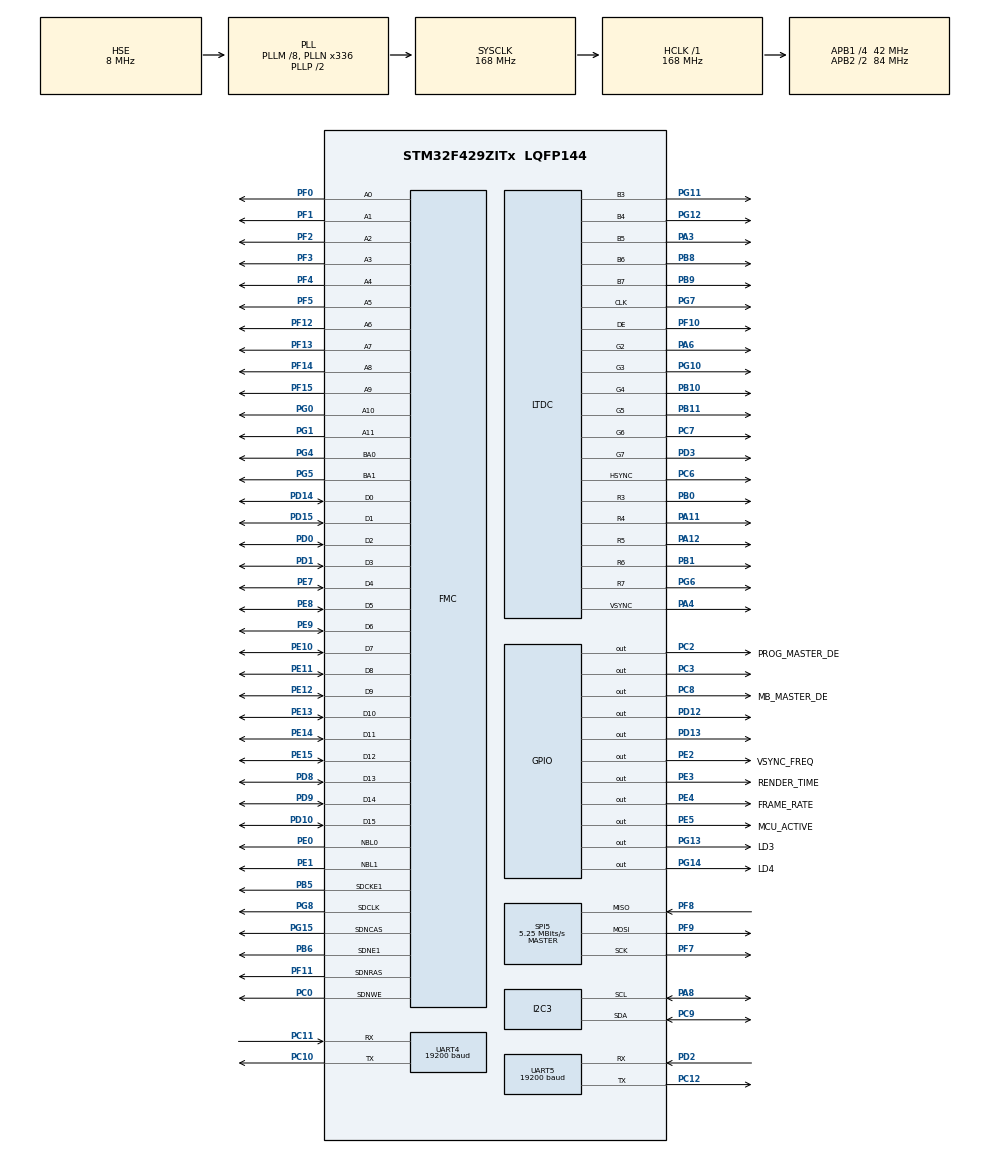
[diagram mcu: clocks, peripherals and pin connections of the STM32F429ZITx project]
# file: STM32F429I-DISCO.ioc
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DMA2D.ColorMode=DMA2D_OUTPUT_RGB565
Dma.Request0=UART5_RX
Dma.Request1=UART5_TX
Dma.Request2=UART4_RX
Dma.Request3=UART4_TX
Dma.UART4_RX.2.Direction=DMA_PERIPH_TO_MEMORY
Dma.UART4_RX.2.FIFOMode=DMA_FIFOMODE_DISABLE
Dma.UART4_RX.2.Instance=DMA1_Stream2
Dma.UART4_RX.2.MemDataAlignment=DMA_MDATAALIGN_BYTE
Dma.UART4_RX.2.MemInc=DMA_MINC_ENABLE
Dma.UART4_RX.2.Mode=DMA_NORMAL
Dma.UART4_RX.2.PeriphDataAlignment=DMA_PDATAALIGN_BYTE
Dma.UART4_RX.2.PeriphInc=DMA_PINC_DISABLE
Dma.UART4_RX.2.Priority=DMA_PRIORITY_LOW
Dma.UART4_TX.3.Direction=DMA_MEMORY_TO_PERIPH
Dma.UART4_TX.3.FIFOMode=DMA_FIFOMODE_DISABLE
Dma.UART4_TX.3.Instance=DMA1_Stream4
Dma.UART4_TX.3.MemDataAlignment=DMA_MDATAALIGN_BYTE
Dma.UART4_TX.3.MemInc=DMA_MINC_ENABLE
Dma.UART4_TX.3.Mode=DMA_NORMAL
Dma.UART4_TX.3.PeriphDataAlignment=DMA_PDATAALIGN_BYTE
Dma.UART4_TX.3.PeriphInc=DMA_PINC_DISABLE
Dma.UART4_TX.3.Priority=DMA_PRIORITY_LOW
Dma.UART5_RX.0.Direction=DMA_PERIPH_TO_MEMORY
Dma.UART5_RX.0.FIFOMode=DMA_FIFOMODE_DISABLE
Dma.UART5_RX.0.Instance=DMA1_Stream0
Dma.UART5_RX.0.MemDataAlignment=DMA_MDATAALIGN_BYTE
Dma.UART5_RX.0.MemInc=DMA_MINC_ENABLE
Dma.UART5_RX.0.Mode=DMA_NORMAL
Dma.UART5_RX.0.PeriphDataAlignment=DMA_PDATAALIGN_BYTE
Dma.UART5_RX.0.PeriphInc=DMA_PINC_DISABLE
Dma.UART5_RX.0.Priority=DMA_PRIORITY_LOW
Dma.UART5_TX.1.Direction=DMA_MEMORY_TO_PERIPH
Dma.UART5_TX.1.FIFOMode=DMA_FIFOMODE_DISABLE
Dma.UART5_TX.1.Instance=DMA1_Stream7
Dma.UART5_TX.1.MemDataAlignment=DMA_MDATAALIGN_BYTE
Dma.UART5_TX.1.MemInc=DMA_MINC_ENABLE
Dma.UART5_TX.1.Mode=DMA_NORMAL
Dma.UART5_TX.1.PeriphDataAlignment=DMA_PDATAALIGN_BYTE
Dma.UART5_TX.1.PeriphInc=DMA_PINC_DISABLE
Dma.UART5_TX.1.Priority=DMA_PRIORITY_LOW
FMC.CASLatency1=FMC_SDRAM_CAS_LATENCY_3
FMC.ExitSelfRefreshDelay1=7
FMC.LoadToActiveDelay1=2
FMC.RCDDelay1=2
FMC.RPDelay1=2
FMC.ReadPipeDelay1=FMC_SDRAM_RPIPE_DELAY_1
FMC.RowCycleDelay1=7
FMC.SDClockPeriod1=FMC_SDRAM_CLOCK_PERIOD_2
FMC.SelfRefreshTime1=4
FMC.WriteRecoveryTime1=3
FREERTOS.BinarySemaphores01=TX_Compl_Sem,Dynamic,NULL,;RX_Compl_Sem,Dynamic,NULL,;PR_TX_Compl_Sem,Dynamic,NULL,;PR_RX_Compl_Sem,Dynamic,NULL,;DataAnalysisStart,Dynamic,NULL,Depleted
FREERTOS.Events01=ReadDataEvent,Dynamic,NULL
FREERTOS.Tasks01=defaultTask,24,128,StartDefaultTask,Default,NULL,Dynamic,NULL,NULL;GUI_Task,24,8192,TouchGFX_Task,As external,NULL,Dynamic,NULL,NULL;DataProcessing,8,128,HandleDataProcessing,Default,NULL,Dynamic,NULL,NULL;ReadData,8,512,ReadDataFunction,Default,NULL,Dynamic,NULL,NULL
FREERTOS.Timers01=DataTimer,Callback01,osTimerPeriodic,Default,NULL,Dynamic,NULL
FREERTOS.configGENERATE_RUN_TIME_STATS=1
FREERTOS.configMAX_PRIORITIES=56
FREERTOS.configRECORD_STACK_HIGH_ADDRESS=1
FREERTOS.configTOTAL_HEAP_SIZE=65536
FREERTOS.configUSE_APPLICATION_TASK_TAG=1
FREERTOS.configUSE_NEWLIB_REENTRANT=1
FREERTOS.configUSE_STATS_FORMATTING_FUNCTIONS=1
I2C3.Analog_Filter=I2C_ANALOGFILTER_DISABLE
LTDC.ActiveH=320
LTDC.ActiveW=240
LTDC.Alpha_L0=255
LTDC.BlendingFactor1_L0=LTDC_BLENDING_FACTOR1_CA
LTDC.BlendingFactor2_L0=LTDC_BLENDING_FACTOR2_CA
LTDC.Blue_L0=0
LTDC.HBP=20
LTDC.HFP=10
LTDC.HSync=10
LTDC.ImageHeight_L0=320
LTDC.ImageWidth_L0=240
LTDC.Layers=0
LTDC.PixelFormat_L0=LTDC_PIXEL_FORMAT_RGB565
LTDC.VFP=4
LTDC.VSync=2
LTDC.WindowX1_L0=240
LTDC.WindowY1_L0=320
Mcu.Family=STM32F4
Mcu.Name=STM32F429ZITx
Mcu.Package=LQFP144
NVIC.DMA1_Stream0_IRQn=true\:5\:0\:false\:false\:true\:true\:false\:true\:true
NVIC.DMA1_Stream2_IRQn=true\:5\:0\:false\:false\:true\:true\:false\:true\:true
NVIC.DMA1_Stream4_IRQn=true\:5\:0\:false\:false\:true\:true\:false\:true\:true
NVIC.DMA1_Stream7_IRQn=true\:5\:0\:false\:false\:true\:true\:false\:true\:true
NVIC.DMA2D_IRQn=true\:5\:0\:true\:false\:true\:false\:true\:true\:true
NVIC.LTDC_IRQn=true\:5\:0\:true\:false\:true\:false\:true\:true\:true
NVIC.PriorityGroup=NVIC_PRIORITYGROUP_4
NVIC.TIM6_DAC_IRQn=true\:0\:0\:false\:false\:true\:false\:false\:true\:true
NVIC.TimeBase=TIM6_DAC_IRQn
NVIC.TimeBaseIP=TIM6
NVIC.UART4_IRQn=true\:5\:0\:false\:false\:true\:true\:true\:true\:true
NVIC.UART5_IRQn=true\:5\:0\:false\:false\:true\:true\:true\:true\:true
PA11.GPIO_Speed=GPIO_SPEED_FREQ_HIGH
PA11.Mode=RGB565
PA11.Signal=LTDC_R4
PA12.GPIO_Speed=GPIO_SPEED_FREQ_HIGH
PA12.Mode=RGB565
PA12.Signal=LTDC_R5
PA3.GPIO_Speed=GPIO_SPEED_FREQ_HIGH
PA3.Mode=RGB565
PA3.Signal=LTDC_B5
PA4.GPIO_Speed=GPIO_SPEED_FREQ_HIGH
PA4.Mode=RGB565
PA4.Signal=LTDC_VSYNC
PA6.GPIO_Speed=GPIO_SPEED_FREQ_HIGH
PA6.Mode=RGB565
PA6.Signal=LTDC_G2
PA8.GPIO_Pu=GPIO_PULLUP
PA8.Mode=I2C
PA8.Signal=I2C3_SCL
PB0.GPIO_Speed=GPIO_SPEED_FREQ_HIGH
PB0.Mode=RGB565
PB0.Signal=LTDC_R3
PB1.GPIO_Speed=GPIO_SPEED_FREQ_HIGH
PB1.Mode=RGB565
PB1.Signal=LTDC_R6
PB10.GPIO_Speed=GPIO_SPEED_FREQ_HIGH
PB10.Mode=RGB565
PB10.Signal=LTDC_G4
PB11.GPIO_Speed=GPIO_SPEED_FREQ_HIGH
PB11.Mode=RGB565
PB11.Signal=LTDC_G5
PB5.Mode=SdramChipSelect2_1
PB5.Signal=FMC_SDCKE1
PB6.Mode=SdramChipSelect2_1
PB6.Signal=FMC_SDNE1
PB8.GPIO_Speed=GPIO_SPEED_FREQ_HIGH
PB8.Mode=RGB565
PB8.Signal=LTDC_B6
PB9.GPIO_Speed=GPIO_SPEED_FREQ_HIGH
PB9.Mode=RGB565
PB9.Signal=LTDC_B7
PC0.Signal=FMC_SDNWE
PC10.Mode=Asynchronous
PC10.Signal=UART4_TX
PC11.Mode=Asynchronous
PC11.Signal=UART4_RX
PC12.Mode=Asynchronous
PC12.Signal=UART5_TX
PC2.GPIO_Label=PROG_MASTER_DE
PC2.Signal=GPIO_Output
PC3.Signal=GPIO_Output
PC6.GPIO_Speed=GPIO_SPEED_FREQ_HIGH
PC6.Mode=RGB565
PC6.Signal=LTDC_HSYNC
PC7.GPIO_Speed=GPIO_SPEED_FREQ_HIGH
PC7.Mode=RGB565
PC7.Signal=LTDC_G6
PC8.GPIO_Label=MB_MASTER_DE
PC8.GPIO_PuPd=GPIO_NOPULL
PC8.Signal=GPIO_Output
PC9.GPIO_Pu=GPIO_PULLUP
PC9.Mode=I2C
PC9.Signal=I2C3_SDA
PD0.Signal=FMC_D2_DA2
PD1.Signal=FMC_D3_DA3
PD10.Signal=FMC_D15_DA15
PD12.GPIO_Speed=GPIO_SPEED_FREQ_HIGH
PD12.Signal=GPIO_Output
PD13.GPIO_Speed=GPIO_SPEED_FREQ_HIGH
PD13.Signal=GPIO_Output
PD14.Signal=FMC_D0_DA0
PD15.Signal=FMC_D1_DA1
PD2.Mode=Asynchronous
PD2.Signal=UART5_RX
PD3.GPIO_Speed=GPIO_SPEED_FREQ_HIGH
PD3.Mode=RGB565
PD3.Signal=LTDC_G7
PD8.Signal=FMC_D13_DA13
PD9.Signal=FMC_D14_DA14
PE0.Signal=FMC_NBL0
PE1.Signal=FMC_NBL1
PE10.Signal=FMC_D7_DA7
PE11.Signal=FMC_D8_DA8
PE12.Signal=FMC_D9_DA9
PE13.Signal=FMC_D10_DA10
PE14.Signal=FMC_D11_DA11
PE15.Signal=FMC_D12_DA12
PE2.GPIO_Label=VSYNC_FREQ
PE2.GPIO_Speed=GPIO_SPEED_FREQ_VERY_HIGH
PE2.Signal=GPIO_Output
PE3.GPIO_Label=RENDER_TIME
PE3.GPIO_Speed=GPIO_SPEED_FREQ_VERY_HIGH
PE3.Signal=GPIO_Output
PE4.GPIO_Label=FRAME_RATE
PE4.GPIO_Speed=GPIO_SPEED_FREQ_VERY_HIGH
PE4.Signal=GPIO_Output
PE5.GPIO_Label=MCU_ACTIVE
PE5.GPIO_Speed=GPIO_SPEED_FREQ_VERY_HIGH
PE5.Signal=GPIO_Output
PE7.Signal=FMC_D4_DA4
PE8.Signal=FMC_D5_DA5
PE9.Signal=FMC_D6_DA6
PF0.Signal=FMC_A0
PF1.Signal=FMC_A1
PF10.GPIO_Speed=GPIO_SPEED_FREQ_HIGH
PF10.Mode=RGB565
PF10.Signal=LTDC_DE
PF11.Signal=FMC_SDNRAS
PF12.Signal=FMC_A6
PF13.Signal=FMC_A7
PF14.Signal=FMC_A8
PF15.Signal=FMC_A9
PF2.Signal=FMC_A2
PF3.Signal=FMC_A3
PF4.Signal=FMC_A4
PF5.Signal=FMC_A5
PF7.Mode=Full_Duplex_Master
PF7.Signal=SPI5_SCK
PF8.Mode=Full_Duplex_Master
PF8.Signal=SPI5_MISO
PF9.Mode=Full_Duplex_Master
PF9.Signal=SPI5_MOSI
PG0.Signal=FMC_A10
PG1.Signal=FMC_A11
PG10.GPIO_Speed=GPIO_SPEED_FREQ_HIGH
PG10.Mode=RGB565
PG10.Signal=LTDC_G3
PG11.GPIO_Speed=GPIO_SPEED_FREQ_HIGH
PG11.Mode=RGB565
PG11.Signal=LTDC_B3
PG12.GPIO_Speed=GPIO_SPEED_FREQ_HIGH
PG12.Mode=RGB565
PG12.Signal=LTDC_B4
PG13.GPIO_Label=LD3
PG13.Signal=GPIO_Output
PG14.GPIO_Label=LD4
PG14.Signal=GPIO_Output
PG15.Signal=FMC_SDNCAS
PG4.Signal=FMC_A14_BA0
PG5.Signal=FMC_A15_BA1
PG6.GPIO_Speed=GPIO_SPEED_FREQ_HIGH
PG6.Mode=RGB565
PG6.Signal=LTDC_R7
PG7.GPIO_Speed=GPIO_SPEED_FREQ_HIGH
PG7.Mode=RGB565
PG7.Signal=LTDC_CLK
PG8.Signal=FMC_SDCLK
PH0/OSC_IN.Mode=HSE-External-Oscillator
PH0/OSC_IN.Signal=RCC_OSC_IN
PH1/OSC_OUT.Mode=HSE-External-Oscillator
PH1/OSC_OUT.Signal=RCC_OSC_OUT
ProjectManager.HeapSize=0xA00
ProjectManager.StackSize=0xA00
ProjectManager.TargetToolchain=STM32CubeIDE
RCC.48MHZClocksFreq_Value=84000000
RCC.AHBFreq_Value=168000000
RCC.APB1CLKDivider=RCC_HCLK_DIV4
RCC.APB1Freq_Value=42000000
RCC.APB1TimFreq_Value=84000000
RCC.APB2CLKDivider=RCC_HCLK_DIV2
RCC.APB2Freq_Value=84000000
RCC.APB2TimFreq_Value=168000000
RCC.CortexFreq_Value=168000000
RCC.HCLKFreq_Value=168000000
RCC.HSE_VALUE=8000000
RCC.HSI_VALUE=16000000
RCC.LSE_VALUE=32768
RCC.PLLM=8
RCC.PLLN=336
RCC.PLLSAIDivR=RCC_PLLSAIDIVR_8
RCC.PLLSAIN=192
RCC.PLLSAIR=4
RCC.PLLSourceVirtual=RCC_PLLSOURCE_HSE
RCC.SYSCLKFreq_VALUE=168000000
RCC.SYSCLKSource=RCC_SYSCLKSOURCE_PLLCLK
RCC.VCOOutputFreq_Value=336000000
SH.FMC_A0.0=FMC_A0,12b-sda1
SH.FMC_A1.0=FMC_A1,12b-sda1
SH.FMC_A10.0=FMC_A10,12b-sda1
SH.FMC_A11.0=FMC_A11,12b-sda1
SH.FMC_A14_BA0.0=FMC_BA0,FourSdramBanks1
SH.FMC_A15_BA1.0=FMC_BA1,FourSdramBanks1
SH.FMC_A2.0=FMC_A2,12b-sda1
SH.FMC_A3.0=FMC_A3,12b-sda1
SH.FMC_A4.0=FMC_A4,12b-sda1
SH.FMC_A5.0=FMC_A5,12b-sda1
SH.FMC_A6.0=FMC_A6,12b-sda1
SH.FMC_A7.0=FMC_A7,12b-sda1
SH.FMC_A8.0=FMC_A8,12b-sda1
SH.FMC_A9.0=FMC_A9,12b-sda1
SH.FMC_D0_DA0.0=FMC_D0,sd-16b-d1
SH.FMC_D10_DA10.0=FMC_D10,sd-16b-d1
SH.FMC_D11_DA11.0=FMC_D11,sd-16b-d1
SH.FMC_D12_DA12.0=FMC_D12,sd-16b-d1
SH.FMC_D13_DA13.0=FMC_D13,sd-16b-d1
SH.FMC_D14_DA14.0=FMC_D14,sd-16b-d1
SH.FMC_D15_DA15.0=FMC_D15,sd-16b-d1
SH.FMC_D1_DA1.0=FMC_D1,sd-16b-d1
SH.FMC_D2_DA2.0=FMC_D2,sd-16b-d1
SH.FMC_D3_DA3.0=FMC_D3,sd-16b-d1
SH.FMC_D4_DA4.0=FMC_D4,sd-16b-d1
SH.FMC_D5_DA5.0=FMC_D5,sd-16b-d1
SH.FMC_D6_DA6.0=FMC_D6,sd-16b-d1
SH.FMC_D7_DA7.0=FMC_D7,sd-16b-d1
SH.FMC_D8_DA8.0=FMC_D8,sd-16b-d1
SH.FMC_D9_DA9.0=FMC_D9,sd-16b-d1
SH.FMC_NBL0.0=FMC_NBL0,Sd2ByteEnable1
SH.FMC_NBL1.0=FMC_NBL1,Sd2ByteEnable1
SH.FMC_SDCLK.0=FMC_SDCLK,12b-sda1
SH.FMC_SDNCAS.0=FMC_SDNCAS,12b-sda1
SH.FMC_SDNRAS.0=FMC_SDNRAS,12b-sda1
SH.FMC_SDNWE.0=FMC_SDNWE,12b-sda1
SPI5.BaudRatePrescaler=SPI_BAUDRATEPRESCALER_16
SPI5.CLKPolarity=SPI_POLARITY_LOW
SPI5.CRCCalculation=SPI_CRCCALCULATION_DISABLE
SPI5.CalculateBaudRate=5.25 MBits/s
SPI5.Direction=SPI_DIRECTION_2LINES
SPI5.Mode=SPI_MODE_MASTER
SPI5.VirtualType=VM_MASTER
UART4.BaudRate=19200
UART4.VirtualMode=Asynchronous
UART5.BaudRate=19200
UART5.VirtualMode=Asynchronous
VP_CRC_VS_CRC.Mode=CRC_Activate
VP_DMA2D_VS_DMA2D.Mode=DMA2D_Activate
VP_FREERTOS_VS_CMSIS_V2.Mode=CMSIS_V2
VP_SYS_VS_tim6.Mode=TIM6
board=custom

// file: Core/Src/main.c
/* USER CODE BEGIN Header */
/**
  ******************************************************************************
  * @file           : main.c
  * @brief          : Main program body
  ******************************************************************************
  * @attention
  *
  * <h2><center>&copy; Copyright (c) 2020 STMicroelectronics.
  * All rights reserved.</center></h2>
  *
  * This software component is licensed by ST under Ultimate Liberty license
  * SLA0044, the "License"; You may not use this file except in compliance with
  * the License. You may obtain a copy of the License at:
  *                             www.st.com/SLA0044
  *
  ******************************************************************************
  */
/* USER CODE END Header */
/* Подключаемые заголовки ----------------------------------------------------*/
#include "main.h"
#include "cmsis_os.h"
#include "app_touchgfx.h"

/* Локальные заголовки -------------------------------------------------------*/
/* USER CODE BEGIN Includes */
#include "Components/ili9341/ili9341.h"
#include "C2CPP.hpp"
#include "CommandReceiver.hpp"
#include "DefrostControl.h"
#include "FreeRTOS.h"

/* Куча FreeRTOS (64 КБ) размещена в основной SRAM (доступна для DMA) */
__attribute__((aligned(8)))
uint8_t ucHeap[65536];  // Явно указываем размер вместо configTOTAL_HEAP_SIZE

/* USER CODE END Includes */

/* Локальные типы ------------------------------------------------------------*/

/* Локальные определения -----------------------------------------------------*/
/* USER CODE BEGIN PD */
#define REFRESH_COUNT           ((uint32_t)1386)   /* счётчик обновления SDRAM */
#define SDRAM_TIMEOUT           ((uint32_t)0xFFFF)

/**
  * @brief  FMC SDRAM Mode definition register defines
  */
#define SDRAM_MODEREG_BURST_LENGTH_1             ((uint16_t)0x0000)
#define SDRAM_MODEREG_BURST_LENGTH_2             ((uint16_t)0x0001)
#define SDRAM_MODEREG_BURST_LENGTH_4             ((uint16_t)0x0002)
#define SDRAM_MODEREG_BURST_LENGTH_8             ((uint16_t)0x0004)
#define SDRAM_MODEREG_BURST_TYPE_SEQUENTIAL      ((uint16_t)0x0000)
#define SDRAM_MODEREG_BURST_TYPE_INTERLEAVED     ((uint16_t)0x0008)
#define SDRAM_MODEREG_CAS_LATENCY_2              ((uint16_t)0x0020)
#define SDRAM_MODEREG_CAS_LATENCY_3              ((uint16_t)0x0030)
#define SDRAM_MODEREG_OPERATING_MODE_STANDARD    ((uint16_t)0x0000)
#define SDRAM_MODEREG_WRITEBURST_MODE_PROGRAMMED ((uint16_t)0x0000)
#define SDRAM_MODEREG_WRITEBURST_MODE_SINGLE     ((uint16_t)0x0200)

#define I2C3_TIMEOUT_MAX                    0x3000 /*<! максимальный таймаут ожидания в циклах I2C */
#define SPI5_TIMEOUT_MAX                    0x1000

#define MSGQUEUE_OBJECTS        9       // единая очередь: телеметрия, лог, ответы на команды
#define MSGQUEUE_OBJECT_SIZE    98     // размер элемента: ServerTxItem_t (type + length + data)
/* USER CODE END PD */

/* Локальные макросы ---------------------------------------------------------*/

/* Локальные переменные ------------------------------------------------------*/
CRC_HandleTypeDef hcrc;

DMA2D_HandleTypeDef hdma2d;

I2C_HandleTypeDef hi2c3;

LTDC_HandleTypeDef hltdc;

SPI_HandleTypeDef hspi5;

UART_HandleTypeDef huart4;
UART_HandleTypeDef huart5;
DMA_HandleTypeDef hdma_uart4_rx;
DMA_HandleTypeDef hdma_uart4_tx;
DMA_HandleTypeDef hdma_uart5_rx;
DMA_HandleTypeDef hdma_uart5_tx;

SDRAM_HandleTypeDef hsdram1;

// ПОТОКИ
/* Описания для defaultTask */
osThreadId_t defaultTaskHandle;
const osThreadAttr_t defaultTask_attributes = {
  .name = "defaultTask",
  .stack_size = 256 * 4,  // Увеличено: запас под служебные вызовы/хуки RTOS
  .priority = (osPriority_t) osPriorityNormal,
};
/* Описания для GUI_Task */
osThreadId_t GUI_TaskHandle;
const osThreadAttr_t GUI_Task_attributes = {
  .name = "GUI_Task",
  .stack_size = 4736 * 4,  // Уменьшено с 5632 до 4736 (экономия ~3.5 КБ для решения проблемы RAM)
  .priority = (osPriority_t) osPriorityNormal,
};
/* Описания для DataProcessing */
osThreadId_t DataProcessingHandle;
const osThreadAttr_t DataProcessing_attributes = {
  .name = "DataProcessing",
  .stack_size = 768 * 4,  // Увеличено: обнаружен stack overflow в задаче DataProcessing
  .priority = (osPriority_t) osPriorityLow,
};
/* Описания для ReadData */
osThreadId_t ReadDataHandle;
const osThreadAttr_t ReadData_attributes = {
  .name = "ReadData",
  .stack_size = 768 * 4,  // Увеличено: Modbus/датчики и сервисные вызовы в одном потоке
  .priority = (osPriority_t) osPriorityLow,
};
/* Описания для RX_From_Server */
osThreadId_t RX_From_ServerHandle;
const osThreadAttr_t RX_From_Server_attributes = {
  .name = "RX_From_Server",
  .stack_size = 768 * 4,  // Увеличено: запас для парсинга команд/параметров и C++-цепочек вызовов
  .priority = (osPriority_t) osPriorityAboveNormal,
};

// ТАЙМЕРЫ
/* Описания для DataTimer */
osTimerId_t DataTimerHandle;
const osTimerAttr_t DataTimer_attributes = {
  .name = "DataTimer"
};
/* Описания для TX_Compl_Sem */
osSemaphoreId_t TX_Compl_SemHandle;
const osSemaphoreAttr_t TX_Compl_Sem_attributes = {
  .name = "TX_Compl_Sem"
};
/* Описания для RX_Compl_Sem */
osSemaphoreId_t RX_Compl_SemHandle;
const osSemaphoreAttr_t RX_Compl_Sem_attributes = {
  .name = "RX_Compl_Sem"
};
/* Описания для PR_TX_Compl_Sem */
osSemaphoreId_t PR_TX_Compl_SemHandle;
const osSemaphoreAttr_t PR_TX_Compl_Sem_attributes = {
  .name = "PR_TX_Compl_Sem"
};
/* Описания для PR_RX_Compl_Sem */
osSemaphoreId_t PR_RX_Compl_SemHandle;
const osSemaphoreAttr_t PR_RX_Compl_Sem_attributes = {
  .name = "PR_RX_Compl_Sem"
};

/* Описания для UART4_CMD_RX_Sem */
osSemaphoreId_t UART4_CMD_RX_SemHandle;
const osSemaphoreAttr_t UART4_CMD_RX_Sem_attributes = {
  .name = "UART4_CMD_RX_Sem"
};

/* Описания для UART4_RX_Event_Sem */
osSemaphoreId_t UART4_RX_Event_SemHandle;
const osSemaphoreAttr_t UART4_RX_Event_Sem_attributes = {
  .name = "UART4_RX_Event_Sem"
};

/* Описания для UART4_Mutex */
osMutexId_t UART4_MutexHandle;
const osMutexAttr_t UART4_Mutex_attributes = {
  .name = "UART4_Mutex"
};
/* Описания для ReadDataEvent */
osEventFlagsId_t ReadDataEventHandle;
const osEventFlagsAttr_t ReadDataEvent_attributes = {
  .name = "ReadDataEvent"
};

/* USER CODE BEGIN PV */
/* Семафор: ответ сервера на переданный пакет (DATA_OK/DATA_FALSE) получен CommandReceiver.
   TX_ToServer() после отправки телеметрии ждёт этот семафор до 100 мс перед следующим osMessageQueueGet. */
osSemaphoreId_t ServerResponseReceived_SemHandle;
const osSemaphoreAttr_t ServerResponseReceived_Sem_attributes = {
  .name = "ServerRespRcvd"
};
// Семафор: окончание процесса считывания с датчиков, начало обработки данных для автоматического регулирования
osSemaphoreId_t SensorsReadDone_SemHandle;
const osSemaphoreAttr_t SensorsReadDone_Sem_attributes = {
  .name = "SensorsReadDone"
};
/* Описания для TX_To_Server */
osThreadId_t TX_To_ServerHandle;
const osThreadAttr_t TX_To_Server_attributes = {
  .name = "TX_To_Server",
  .stack_size = 768 * 4,  // Увеличено: ранее фиксировался overflow; оставляем стабильный запас
  .priority = (osPriority_t) osPriorityLow,
};

/* Единая очередь отправки на сервер (телеметрия, лог, ответы на команды) */
osMessageQueueId_t Data_QueueHandle;
osMessageQueueId_t Telemetry_QueueHandle;
const osMessageQueueAttr_t Data_Queue_attributes = {
  .name = "Data_Queue"
};

/* USER CODE END PV */

/* Прототипы локальных функций ----------------------------------------------*/
void SystemClock_Config(void);
static void MX_GPIO_Init(void);
static void MX_DMA_Init(void);
static void MX_CRC_Init(void);
static void MX_I2C3_Init(void);
static void MX_SPI5_Init(void);
static void MX_FMC_Init(void);
static void MX_LTDC_Init(void);
static void MX_DMA2D_Init(void);
static void MX_UART5_Init(void);
static void MX_UART4_Init(void);
void StartDefaultTask(void *argument);
extern void TouchGFX_Task(void *argument);
void HandleDataProcessing(void *argument);
void ReadDataFunction(void *argument);
void Callback01(void *argument);

/* USER CODE BEGIN PFP */
static void BSP_SDRAM_Initialization_Sequence(SDRAM_HandleTypeDef *hsdram, FMC_SDRAM_CommandTypeDef *Command);
void TransferToServer(void *argument);

static uint8_t            I2C3_ReadData(uint8_t Addr, uint8_t Reg);
static void               I2C3_WriteData(uint8_t Addr, uint8_t Reg, uint8_t Value);
static uint8_t            I2C3_ReadBuffer(uint8_t Addr, uint8_t Reg, uint8_t *pBuffer, uint16_t Length);

/* Функции шины SPIx */
static void               SPI5_Write(uint16_t Value);
static uint32_t           SPI5_Read(uint8_t ReadSize);
static void               SPI5_Error(void);

/* Связующие функции для LCD периферии */
void                      LCD_IO_Init(void);
void                      LCD_IO_WriteData(uint16_t RegValue);
void                      LCD_IO_WriteReg(uint8_t Reg);
uint32_t                  LCD_IO_ReadData(uint16_t RegValue, uint8_t ReadSize);
void                      LCD_Delay(uint32_t delay);

/* IO-функции расширителя ввода-вывода */
void                      IOE_Init(void);
void                      IOE_ITConfig(void);
void                      IOE_Delay(uint32_t Delay);
void                      IOE_Write(uint8_t Addr, uint8_t Reg, uint8_t Value);
uint8_t                   IOE_Read(uint8_t Addr, uint8_t Reg);
uint16_t                  IOE_ReadMultiple(uint8_t Addr, uint8_t Reg, uint8_t *pBuffer, uint16_t Length);

/* USER CODE END PFP */

/* Пользовательский код ------------------------------------------------------*/
/* USER CODE BEGIN 0 */
static LCD_DrvTypeDef* LcdDrv;

uint32_t I2c3Timeout = I2C3_TIMEOUT_MAX; /*<! таймаут при сбое обмена по I2C */
uint32_t Spi5Timeout = SPI5_TIMEOUT_MAX; /*<! таймаут при сбое обмена по SPI */

/* Диагностика перезапусков:
 * g_bootFaultMarker/g_bootFaultCounter хранятся в .noinit и переживают программный reset.
 * g_bootResetFlagsSnapshot — снимок флагов RCC_CSR на старте (очищается после чтения). */
#if defined(__GNUC__)
__attribute__((section(".noinit"))) volatile uint32_t g_bootFaultMarker;
__attribute__((section(".noinit"))) volatile uint32_t g_bootFaultCounter;
#else
volatile uint32_t g_bootFaultMarker = BOOT_FAULT_MARKER_NONE;
volatile uint32_t g_bootFaultCounter = 0u;
#endif
volatile uint32_t g_bootResetFlagsSnapshot = 0u;

void BootDiag_CaptureResetFlags(void)
{
  uint32_t flags = 0u;
  if (__HAL_RCC_GET_FLAG(RCC_FLAG_PORRST) != RESET)  flags |= (1u << 0);
  if (__HAL_RCC_GET_FLAG(RCC_FLAG_PINRST) != RESET)  flags |= (1u << 1);
  if (__HAL_RCC_GET_FLAG(RCC_FLAG_SFTRST) != RESET)  flags |= (1u << 2);
  if (__HAL_RCC_GET_FLAG(RCC_FLAG_IWDGRST) != RESET) flags |= (1u << 3);
  if (__HAL_RCC_GET_FLAG(RCC_FLAG_WWDGRST) != RESET) flags |= (1u << 4);
  if (__HAL_RCC_GET_FLAG(RCC_FLAG_LPWRRST) != RESET) flags |= (1u << 5);
  if (__HAL_RCC_GET_FLAG(RCC_FLAG_BORRST) != RESET)  flags |= (1u << 6);
  g_bootResetFlagsSnapshot = flags;
  /* На "холодном" старте сбрасываем маркеры прошлых падений. */
  if ((flags & (1u << 0)) != 0u || (flags & (1u << 6)) != 0u) {
    g_bootFaultMarker = BOOT_FAULT_MARKER_NONE;
    g_bootFaultCounter = 0u;
  }
  __HAL_RCC_CLEAR_RESET_FLAGS();
}
/* USER CODE END 0 */

int main(void)
{

  /* Конфигурация MCU --------------------------------------------------------*/

  /* Сброс всех периферийных блоков, инициализация Flash и SysTick. */
  HAL_Init();

  /* USER CODE BEGIN Init */
  /* Снимаем и очищаем флаги причин перезапуска как можно раньше. */
  BootDiag_CaptureResetFlags();

  /* USER CODE END Init */

  /* Настройка системной частоты */
  SystemClock_Config();

  /* Инициализация всех настроенных периферийных блоков */
  MX_GPIO_Init();
  MX_DMA_Init();
  MX_CRC_Init();
  MX_I2C3_Init();
  MX_SPI5_Init();
  MX_FMC_Init();
  MX_LTDC_Init();
  MX_DMA2D_Init();
  MX_UART5_Init();
  MX_UART4_Init();
  MX_TouchGFX_Init();
  /* Вызов функции PreOsInit */
  MX_TouchGFX_PreOSInit();
  /* USER CODE BEGIN 2 */

  // ═══════════════════════════════════════════════════════════════════════════
  // КРИТИЧНО: Гарантируем режим приёма (DE = 0) перед запуском RTOS
  // Дополнительная защита на случай сбоев при инициализации
  // ═══════════════════════════════════════════════════════════════════════════
  HAL_GPIO_WritePin(PROG_MASTER_DE_GPIO_Port, PROG_MASTER_DE_Pin, GPIO_PIN_RESET);
  HAL_GPIO_WritePin(MB_MASTER_DE_GPIO_Port, MB_MASTER_DE_Pin, GPIO_PIN_RESET);

  /* Инициализация модуля дефроста (загрузка/дефолт параметров, сброс состояния) */
  DefrostControl_Init();

  /* USER CODE END 2 */

  /* Инициализация планировщика */
  osKernelInitialize();

  /* Создание семафоров */
  /* creation of TX_Compl_Sem */
  TX_Compl_SemHandle = osSemaphoreNew(1, 0, &TX_Compl_Sem_attributes);

  /* creation of RX_Compl_Sem */
  RX_Compl_SemHandle = osSemaphoreNew(1, 0, &RX_Compl_Sem_attributes);

  /* creation of PR_TX_Compl_Sem */
  PR_TX_Compl_SemHandle = osSemaphoreNew(1, 0, &PR_TX_Compl_Sem_attributes);

  /* creation of PR_RX_Compl_Sem */
  PR_RX_Compl_SemHandle = osSemaphoreNew(1, 0, &PR_RX_Compl_Sem_attributes);

  /* creation of UART4_CMD_RX_Sem */
  UART4_CMD_RX_SemHandle = osSemaphoreNew(1, 0, &UART4_CMD_RX_Sem_attributes);

  /* creation of UART4_RX_Event_Sem */
  UART4_RX_Event_SemHandle = osSemaphoreNew(1, 0, &UART4_RX_Event_Sem_attributes);

  /* creation of UART4_Mutex */
  UART4_MutexHandle = osMutexNew(&UART4_Mutex_attributes);

  /* USER CODE BEGIN RTOS_SEMAPHORES */
  ServerResponseReceived_SemHandle = osSemaphoreNew(1, 0, &ServerResponseReceived_Sem_attributes);
  SensorsReadDone_SemHandle = osSemaphoreNew(1, 0, &SensorsReadDone_Sem_attributes);
 /* USER CODE END RTOS_SEMAPHORES */

  /* Создание таймеров */
  /* creation of DataTimer */
  DataTimerHandle = osTimerNew(Callback01, osTimerPeriodic, NULL, &DataTimer_attributes);
  if (DataTimerHandle == NULL) {
    /* Таймер не создан: не хватило heap (configTOTAL_HEAP_SIZE / ucHeap).
       DataTimerFunc() вызываться не будет, светодиод не мигает. */
    Error_Handler();
  }

  /* USER CODE BEGIN RTOS_TIMERS */
  /* start timers, add new ones, ... */
  osTimerStart(DataTimerHandle, 1000);
  /* USER CODE END RTOS_TIMERS */

  /* USER CODE BEGIN RTOS_QUEUES */
  /* Единая очередь отправки на сервер */
  Data_QueueHandle = osMessageQueueNew (MSGQUEUE_OBJECTS, MSGQUEUE_OBJECT_SIZE, &Data_Queue_attributes);
  Telemetry_QueueHandle = osMessageQueueNew(4u, MSGQUEUE_OBJECT_SIZE, NULL);
  /* USER CODE END RTOS_QUEUES */

  /* Создание потоков */
  /* creation of defaultTask */
  defaultTaskHandle = osThreadNew(StartDefaultTask, NULL, &defaultTask_attributes);
  /* creation of GUI_Task */
  GUI_TaskHandle = osThreadNew(TouchGFX_Task, NULL, &GUI_Task_attributes);

  /* USER CODE BEGIN RTOS_THREADS */
  /* creation of DataProcessing */
  DataProcessingHandle = osThreadNew(HandleDataProcessing, NULL, &DataProcessing_attributes);
  /* creation of ReadData */
  ReadDataHandle = osThreadNew(ReadDataFunction, NULL, &ReadData_attributes);
  /* creation of TX_To_Server */
  TX_To_ServerHandle = osThreadNew(TransferToServer, NULL, &TX_To_Server_attributes);
  /* creation of RX_From_Server */
  RX_From_ServerHandle = osThreadNew(CommandReceiver_Task_C, NULL, &RX_From_Server_attributes);
  /* USER CODE END RTOS_THREADS */

  /* Создание событий */

  /* USER CODE BEGIN RTOS_EVENTS */
  /* creation of ReadDataEvent */
  ReadDataEventHandle = osEventFlagsNew(&ReadDataEvent_attributes);
  /* USER CODE END RTOS_EVENTS */

  /* Запуск планировщика */
  osKernelStart();

  /* Сюда не должны попадать: управление передано планировщику */
  /* Бесконечный цикл */
  while (1)
  {

  }
}

void SystemClock_Config(void)
{
  RCC_OscInitTypeDef RCC_OscInitStruct = {0};
  RCC_ClkInitTypeDef RCC_ClkInitStruct = {0};

  /** Configure the main internal regulator output voltage
  */
  __HAL_RCC_PWR_CLK_ENABLE();
  __HAL_PWR_VOLTAGESCALING_CONFIG(PWR_REGULATOR_VOLTAGE_SCALE1);

  /** Initializes the RCC Oscillators according to the specified parameters
  * in the RCC_OscInitTypeDef structure.
  */
  RCC_OscInitStruct.OscillatorType = RCC_OSCILLATORTYPE_HSE;
  RCC_OscInitStruct.HSEState = RCC_HSE_ON;
  RCC_OscInitStruct.PLL.PLLState = RCC_PLL_ON;
  RCC_OscInitStruct.PLL.PLLSource = RCC_PLLSOURCE_HSE;
  RCC_OscInitStruct.PLL.PLLM = 8;
  RCC_OscInitStruct.PLL.PLLN = 336;
  RCC_OscInitStruct.PLL.PLLP = RCC_PLLP_DIV2;
  RCC_OscInitStruct.PLL.PLLQ = 4;
  if (HAL_RCC_OscConfig(&RCC_OscInitStruct) != HAL_OK)
  {
    Error_Handler();
  }

  /** Initializes the CPU, AHB and APB buses clocks
  */
  RCC_ClkInitStruct.ClockType = RCC_CLOCKTYPE_HCLK|RCC_CLOCKTYPE_SYSCLK
                              |RCC_CLOCKTYPE_PCLK1|RCC_CLOCKTYPE_PCLK2;
  RCC_ClkInitStruct.SYSCLKSource = RCC_SYSCLKSOURCE_PLLCLK;
  RCC_ClkInitStruct.AHBCLKDivider = RCC_SYSCLK_DIV1;
  RCC_ClkInitStruct.APB1CLKDivider = RCC_HCLK_DIV4;
  RCC_ClkInitStruct.APB2CLKDivider = RCC_HCLK_DIV2;

  if (HAL_RCC_ClockConfig(&RCC_ClkInitStruct, FLASH_LATENCY_5) != HAL_OK)
  {
    Error_Handler();
  }
}

static void MX_CRC_Init(void)
{

  hcrc.Instance = CRC;
  if (HAL_CRC_Init(&hcrc) != HAL_OK)
  {
    Error_Handler();
  }

}

static void MX_DMA2D_Init(void)
{

  hdma2d.Instance = DMA2D;
  hdma2d.Init.Mode = DMA2D_M2M;
  hdma2d.Init.ColorMode = DMA2D_OUTPUT_RGB565;
  hdma2d.Init.OutputOffset = 0;
  hdma2d.LayerCfg[1].InputOffset = 0;
  hdma2d.LayerCfg[1].InputColorMode = DMA2D_INPUT_RGB565;
  hdma2d.LayerCfg[1].AlphaMode = DMA2D_NO_MODIF_ALPHA;
  hdma2d.LayerCfg[1].InputAlpha = 0;
  if (HAL_DMA2D_Init(&hdma2d) != HAL_OK)
  {
    Error_Handler();
  }
  if (HAL_DMA2D_ConfigLayer(&hdma2d, 1) != HAL_OK)
  {
    Error_Handler();
  }

}

static void MX_I2C3_Init(void)
{

  hi2c3.Instance = I2C3;
  hi2c3.Init.ClockSpeed = 100000;
  hi2c3.Init.DutyCycle = I2C_DUTYCYCLE_2;
  hi2c3.Init.OwnAddress1 = 0;
  hi2c3.Init.AddressingMode = I2C_ADDRESSINGMODE_7BIT;
  hi2c3.Init.DualAddressMode = I2C_DUALADDRESS_DISABLE;
  hi2c3.Init.OwnAddress2 = 0;
  hi2c3.Init.GeneralCallMode = I2C_GENERALCALL_DISABLE;
  hi2c3.Init.NoStretchMode = I2C_NOSTRETCH_DISABLE;
  if (HAL_I2C_Init(&hi2c3) != HAL_OK)
  {
    Error_Handler();
  }

  /** Configure Analogue filter
  */
  if (HAL_I2CEx_ConfigAnalogFilter(&hi2c3, I2C_ANALOGFILTER_DISABLE) != HAL_OK)
  {
    Error_Handler();
  }

  /** Configure Digital filter
  */
  if (HAL_I2CEx_ConfigDigitalFilter(&hi2c3, 0) != HAL_OK)
  {
    Error_Handler();
  }

}

static void MX_LTDC_Init(void)
{

  LTDC_LayerCfgTypeDef pLayerCfg = {0};

  hltdc.Instance = LTDC;
  hltdc.Init.HSPolarity = LTDC_HSPOLARITY_AL;
  hltdc.Init.VSPolarity = LTDC_VSPOLARITY_AL;
  hltdc.Init.DEPolarity = LTDC_DEPOLARITY_AL;
  hltdc.Init.PCPolarity = LTDC_PCPOLARITY_IPC;
  hltdc.Init.HorizontalSync = 9;
  hltdc.Init.VerticalSync = 1;
  hltdc.Init.AccumulatedHBP = 29;
  hltdc.Init.AccumulatedVBP = 3;
  hltdc.Init.AccumulatedActiveW = 269;
  hltdc.Init.AccumulatedActiveH = 323;
  hltdc.Init.TotalWidth = 279;
  hltdc.Init.TotalHeigh = 327;
  hltdc.Init.Backcolor.Blue = 0;
  hltdc.Init.Backcolor.Green = 0;
  hltdc.Init.Backcolor.Red = 0;
  if (HAL_LTDC_Init(&hltdc) != HAL_OK)
  {
    Error_Handler();
  }
  pLayerCfg.WindowX0 = 0;
  pLayerCfg.WindowX1 = 240;
  pLayerCfg.WindowY0 = 0;
  pLayerCfg.WindowY1 = 320;
  pLayerCfg.PixelFormat = LTDC_PIXEL_FORMAT_RGB565;
  pLayerCfg.Alpha = 255;
  pLayerCfg.Alpha0 = 0;
  pLayerCfg.BlendingFactor1 = LTDC_BLENDING_FACTOR1_CA;
  pLayerCfg.BlendingFactor2 = LTDC_BLENDING_FACTOR2_CA;
  pLayerCfg.FBStartAdress = 0;
  pLayerCfg.ImageWidth = 240;
  pLayerCfg.ImageHeight = 320;
  pLayerCfg.Backcolor.Blue = 0;
  pLayerCfg.Backcolor.Green = 0;
  pLayerCfg.Backcolor.Red = 0;
  if (HAL_LTDC_ConfigLayer(&hltdc, &pLayerCfg, 0) != HAL_OK)
  {
    Error_Handler();
  }
  /* USER CODE BEGIN LTDC_Init 2 */
    /*Select the device */
  LcdDrv = &ili9341_drv;
  /* LCD Init */
  LcdDrv->Init();

  LcdDrv->DisplayOff();
  /* USER CODE END LTDC_Init 2 */

}

static void MX_SPI5_Init(void)
{

  /* SPI5 parameter configuration*/
  hspi5.Instance = SPI5;
  hspi5.Init.Mode = SPI_MODE_MASTER;
  hspi5.Init.Direction = SPI_DIRECTION_2LINES;
  hspi5.Init.DataSize = SPI_DATASIZE_8BIT;
  hspi5.Init.CLKPolarity = SPI_POLARITY_LOW;
  hspi5.Init.CLKPhase = SPI_PHASE_1EDGE;
  hspi5.Init.NSS = SPI_NSS_SOFT;
  hspi5.Init.BaudRatePrescaler = SPI_BAUDRATEPRESCALER_16;
  hspi5.Init.FirstBit = SPI_FIRSTBIT_MSB;
  hspi5.Init.TIMode = SPI_TIMODE_DISABLE;
  hspi5.Init.CRCCalculation = SPI_CRCCALCULATION_DISABLE;
  hspi5.Init.CRCPolynomial = 10;
  if (HAL_SPI_Init(&hspi5) != HAL_OK)
  {
    Error_Handler();
  }

}

static void MX_UART4_Init(void)
{

  huart4.Instance = UART4;
  huart4.Init.BaudRate = 19200;
  huart4.Init.WordLength = UART_WORDLENGTH_8B;
  huart4.Init.StopBits = UART_STOPBITS_1;
  huart4.Init.Parity = UART_PARITY_NONE;
  huart4.Init.Mode = UART_MODE_TX_RX;
  huart4.Init.HwFlowCtl = UART_HWCONTROL_NONE;
  huart4.Init.OverSampling = UART_OVERSAMPLING_16;
  if (HAL_UART_Init(&huart4) != HAL_OK)
  {
    Error_Handler();
  }

}

static void MX_UART5_Init(void)
{

  huart5.Instance = UART5;
  huart5.Init.BaudRate = 19200;
  huart5.Init.WordLength = UART_WORDLENGTH_8B;
  huart5.Init.StopBits = UART_STOPBITS_1;
  huart5.Init.Parity = UART_PARITY_NONE;
  huart5.Init.Mode = UART_MODE_TX_RX;
  huart5.Init.HwFlowCtl = UART_HWCONTROL_NONE;
  huart5.Init.OverSampling = UART_OVERSAMPLING_16;
  if (HAL_UART_Init(&huart5) != HAL_OK)
  {
    Error_Handler();
  }

}

static void MX_DMA_Init(void)
{

  /* DMA controller clock enable */
  __HAL_RCC_DMA1_CLK_ENABLE();

  /* DMA interrupt init */
  /* DMA1_Stream0_IRQn interrupt configuration */
  HAL_NVIC_SetPriority(DMA1_Stream0_IRQn, 5, 0);
  HAL_NVIC_EnableIRQ(DMA1_Stream0_IRQn);
  /* DMA1_Stream2_IRQn interrupt configuration */
  HAL_NVIC_SetPriority(DMA1_Stream2_IRQn, 5, 0);
  HAL_NVIC_EnableIRQ(DMA1_Stream2_IRQn);
  /* DMA1_Stream4_IRQn interrupt configuration */
  HAL_NVIC_SetPriority(DMA1_Stream4_IRQn, 5, 0);
  HAL_NVIC_EnableIRQ(DMA1_Stream4_IRQn);
  /* DMA1_Stream7_IRQn interrupt configuration */
  HAL_NVIC_SetPriority(DMA1_Stream7_IRQn, 5, 0);
  HAL_NVIC_EnableIRQ(DMA1_Stream7_IRQn);

}

/* FMC initialization function */
static void MX_FMC_Init(void)
{

  FMC_SDRAM_TimingTypeDef SdramTiming = {0};

  /** Perform the SDRAM1 memory initialization sequence
  */
  hsdram1.Instance = FMC_SDRAM_DEVICE;
  /* hsdram1.Init */
  hsdram1.Init.SDBank = FMC_SDRAM_BANK2;
  hsdram1.Init.ColumnBitsNumber = FMC_SDRAM_COLUMN_BITS_NUM_8;
  hsdram1.Init.RowBitsNumber = FMC_SDRAM_ROW_BITS_NUM_12;
  hsdram1.Init.MemoryDataWidth = FMC_SDRAM_MEM_BUS_WIDTH_16;
  hsdram1.Init.InternalBankNumber = FMC_SDRAM_INTERN_BANKS_NUM_4;
  hsdram1.Init.CASLatency = FMC_SDRAM_CAS_LATENCY_3;
  hsdram1.Init.WriteProtection = FMC_SDRAM_WRITE_PROTECTION_DISABLE;
  hsdram1.Init.SDClockPeriod = FMC_SDRAM_CLOCK_PERIOD_2;
  hsdram1.Init.ReadBurst = FMC_SDRAM_RBURST_DISABLE;
  hsdram1.Init.ReadPipeDelay = FMC_SDRAM_RPIPE_DELAY_1;
  /* SdramTiming */
  SdramTiming.LoadToActiveDelay = 2;
  SdramTiming.ExitSelfRefreshDelay = 7;
  SdramTiming.SelfRefreshTime = 4;
  SdramTiming.RowCycleDelay = 7;
  SdramTiming.WriteRecoveryTime = 3;
  SdramTiming.RPDelay = 2;
  SdramTiming.RCDDelay = 2;

  if (HAL_SDRAM_Init(&hsdram1, &SdramTiming) != HAL_OK)
  {
    Error_Handler( );
  }

  /* USER CODE BEGIN FMC_Init 2 */

  FMC_SDRAM_CommandTypeDef command;

  /* Program the SDRAM external device */
  BSP_SDRAM_Initialization_Sequence(&hsdram1, &command);
  /* USER CODE END FMC_Init 2 */
}

static void MX_GPIO_Init(void)
{
  GPIO_InitTypeDef GPIO_InitStruct = {0};

  /* GPIO Ports Clock Enable */
  __HAL_RCC_GPIOE_CLK_ENABLE();
  __HAL_RCC_GPIOF_CLK_ENABLE();
  __HAL_RCC_GPIOH_CLK_ENABLE();
  __HAL_RCC_GPIOC_CLK_ENABLE();
  __HAL_RCC_GPIOA_CLK_ENABLE();
  __HAL_RCC_GPIOB_CLK_ENABLE();
  __HAL_RCC_GPIOG_CLK_ENABLE();
  __HAL_RCC_GPIOD_CLK_ENABLE();

  /*Configure GPIO pin Output Level */
  HAL_GPIO_WritePin(GPIOE, VSYNC_FREQ_Pin|RENDER_TIME_Pin|FRAME_RATE_Pin|MCU_ACTIVE_Pin, GPIO_PIN_RESET);

  /*Configure GPIO pin Output Level */
  HAL_GPIO_WritePin(GPIOC, PROG_MASTER_DE_Pin|GPIO_PIN_2|GPIO_PIN_3|MB_MASTER_DE_Pin, GPIO_PIN_RESET);

  /*Configure GPIO pin Output Level */
  HAL_GPIO_WritePin(GPIOD, GPIO_PIN_12|GPIO_PIN_13, GPIO_PIN_RESET);

  /*Configure GPIO pin Output Level */
  HAL_GPIO_WritePin(GPIOG, LD3_Pin|LD4_Pin, GPIO_PIN_RESET);

  /*Configure GPIO pins : VSYNC_FREQ_Pin RENDER_TIME_Pin FRAME_RATE_Pin MCU_ACTIVE_Pin */
  GPIO_InitStruct.Pin = VSYNC_FREQ_Pin|RENDER_TIME_Pin|FRAME_RATE_Pin|MCU_ACTIVE_Pin;
  GPIO_InitStruct.Mode = GPIO_MODE_OUTPUT_PP;
  GPIO_InitStruct.Pull = GPIO_NOPULL;
  GPIO_InitStruct.Speed = GPIO_SPEED_FREQ_VERY_HIGH;
  HAL_GPIO_Init(GPIOE, &GPIO_InitStruct);

  /*Configure GPIO pins : PROG_MASTER_DE_Pin PC2 PC3 MB_MASTER_DE_Pin */
  GPIO_InitStruct.Pin = PROG_MASTER_DE_Pin|GPIO_PIN_2|GPIO_PIN_3|MB_MASTER_DE_Pin;
  GPIO_InitStruct.Mode = GPIO_MODE_OUTPUT_PP;
  GPIO_InitStruct.Pull = GPIO_NOPULL;
  GPIO_InitStruct.Speed = GPIO_SPEED_FREQ_LOW;
  HAL_GPIO_Init(GPIOC, &GPIO_InitStruct);

  /*Configure GPIO pins : PD12 PD13 */
  GPIO_InitStruct.Pin = GPIO_PIN_12|GPIO_PIN_13;
  GPIO_InitStruct.Mode = GPIO_MODE_OUTPUT_PP;
  GPIO_InitStruct.Pull = GPIO_NOPULL;
  GPIO_InitStruct.Speed = GPIO_SPEED_FREQ_HIGH;
  HAL_GPIO_Init(GPIOD, &GPIO_InitStruct);

  /*Configure GPIO pins : LD3_Pin LD4_Pin */
  GPIO_InitStruct.Pin = LD3_Pin|LD4_Pin;
  GPIO_InitStruct.Mode = GPIO_MODE_OUTPUT_PP;
  GPIO_InitStruct.Pull = GPIO_NOPULL;
  GPIO_InitStruct.Speed = GPIO_SPEED_FREQ_LOW;
  HAL_GPIO_Init(GPIOG, &GPIO_InitStruct);

}

/* USER CODE BEGIN 4 */
/**
  * @brief  Perform the SDRAM external memory initialization sequence
  * @param  hsdram: SDRAM handle
  * @param  Command: Pointer to SDRAM command structure
  * @retval None
  */
static void BSP_SDRAM_Initialization_Sequence(SDRAM_HandleTypeDef *hsdram, FMC_SDRAM_CommandTypeDef *Command)
{
 __IO uint32_t tmpmrd =0;

  /* Шаг 1: включение тактирования SDRAM */
  Command->CommandMode             = FMC_SDRAM_CMD_CLK_ENABLE;
  Command->CommandTarget           = FMC_SDRAM_CMD_TARGET_BANK2;
  Command->AutoRefreshNumber       = 1;
  Command->ModeRegisterDefinition  = 0;

  /* Send the command */
  HAL_SDRAM_SendCommand(hsdram, Command, SDRAM_TIMEOUT);

  /* Шаг 2: минимальная задержка 100 мкс */
  /* Inserted delay is equal to 1 ms due to systick time base unit (ms) */
  HAL_Delay(1);

  /* Шаг 3: команда PALL (предзаряд всех банков) */
  Command->CommandMode             = FMC_SDRAM_CMD_PALL;
  Command->CommandTarget           = FMC_SDRAM_CMD_TARGET_BANK2;
  Command->AutoRefreshNumber       = 1;
  Command->ModeRegisterDefinition  = 0;

  /* Send the command */
  HAL_SDRAM_SendCommand(hsdram, Command, SDRAM_TIMEOUT);

  /* Шаг 4: команда Auto Refresh */
  Command->CommandMode             = FMC_SDRAM_CMD_AUTOREFRESH_MODE;
  Command->CommandTarget           = FMC_SDRAM_CMD_TARGET_BANK2;
  Command->AutoRefreshNumber       = 4;
  Command->ModeRegisterDefinition  = 0;

  /* Send the command */
  HAL_SDRAM_SendCommand(hsdram, Command, SDRAM_TIMEOUT);

  /* Шаг 5: программирование регистра режима внешней памяти */
  tmpmrd = (uint32_t)SDRAM_MODEREG_BURST_LENGTH_1          |
                     SDRAM_MODEREG_BURST_TYPE_SEQUENTIAL   |
                     SDRAM_MODEREG_CAS_LATENCY_3           |
                     SDRAM_MODEREG_OPERATING_MODE_STANDARD |
                     SDRAM_MODEREG_WRITEBURST_MODE_SINGLE;

  Command->CommandMode             = FMC_SDRAM_CMD_LOAD_MODE;
  Command->CommandTarget           = FMC_SDRAM_CMD_TARGET_BANK2;
  Command->AutoRefreshNumber       = 1;
  Command->ModeRegisterDefinition  = tmpmrd;

  /* Send the command */
  HAL_SDRAM_SendCommand(hsdram, Command, SDRAM_TIMEOUT);

  /* Шаг 6: установка счётчика обновления */
  /* Установка частоты обновления устройства */
  HAL_SDRAM_ProgramRefreshRate(hsdram, REFRESH_COUNT);
}

/**
  * @brief  Низкоуровневая инициализация IOE.
  */
void IOE_Init(void)
{
  // Пустая функция: инициализация STMPE811 для I2C выполняется в CubeMX, поэтому здесь не требуется.
}

/**
  * @brief  Низкоуровневая настройка прерываний IOE.
  */
void IOE_ITConfig(void)
{
  // Пустая функция: настройка прерываний STMPE811 не используется в этом проекте.
}

/**
  * @brief  IOE: запись одного байта данных.
  * @param  Addr: адрес I2C
  * @param  Reg: адрес регистра
  * @param  Value: записываемые данные
  */
void IOE_Write(uint8_t Addr, uint8_t Reg, uint8_t Value)
{
  I2C3_WriteData(Addr, Reg, Value);
}

/**
  * @brief  IOE: чтение одного байта данных.
  * @param  Addr: адрес I2C
  * @param  Reg: адрес регистра
  * @retval прочитанные данные
  */
uint8_t IOE_Read(uint8_t Addr, uint8_t Reg)
{
  return I2C3_ReadData(Addr, Reg);
}

/**
  * @brief  IOE: чтение нескольких байт данных.
  * @param  Addr: адрес I2C
  * @param  Reg: адрес регистра
  * @param  pBuffer: указатель на буфер данных
  * @param  Length: длина данных
  * @retval 0 при успешном чтении
  */
uint16_t IOE_ReadMultiple(uint8_t Addr, uint8_t Reg, uint8_t *pBuffer, uint16_t Length)
{
 return I2C3_ReadBuffer(Addr, Reg, pBuffer, Length);
}

/**
  * @brief  Задержка IOE.
  * @param  Delay задержка в мс
  */
void IOE_Delay(uint32_t Delay)
{
  HAL_Delay(Delay);
}

/**
  * @brief  Запись значения в регистр устройства по шине.
  * @param  Addr: адрес устройства на шине
  * @param  Reg: адрес регистра для записи
  * @param  Value: значение для записи
  */
static void I2C3_WriteData(uint8_t Addr, uint8_t Reg, uint8_t Value)
{
  if (!I2C3_BusLock()) return;
  HAL_StatusTypeDef status = HAL_OK;

  status = HAL_I2C_Mem_Write(&hi2c3, Addr, (uint16_t)Reg, I2C_MEMADD_SIZE_8BIT, &Value, 1, I2c3Timeout);
  I2C3_BusUnlock();

  /* Проверка статуса обмена */
  if(status != HAL_OK)
  {
    /* Переинициализация шины */
    //I2Cx_Error();
  }
}

/**
  * @brief  Чтение регистра устройства по шине.
  * @param  Addr: адрес устройства на шине
  * @param  Reg: адрес регистра
  * @retval данные, прочитанные по адресу регистра
  */
static uint8_t I2C3_ReadData(uint8_t Addr, uint8_t Reg)
{
  if (!I2C3_BusLock()) return 0;
  HAL_StatusTypeDef status = HAL_OK;
  uint8_t value = 0;

  status = HAL_I2C_Mem_Read(&hi2c3, Addr, Reg, I2C_MEMADD_SIZE_8BIT, &value, 1, I2c3Timeout);
  I2C3_BusUnlock();

  /* Проверка статуса обмена */
  if(status != HAL_OK)
  {
    /* Переинициализация шины */
    //I2Cx_Error();

  }
  return value;
}

/**
  * @brief  Чтение нескольких байт по шине.
  * @param  Addr: адрес I2C
  * @param  Reg: адрес регистра
  * @param  pBuffer: указатель на буфер для чтения
  * @param  Length: длина данных
  * @retval 0 при успешном чтении
  */
static uint8_t I2C3_ReadBuffer(uint8_t Addr, uint8_t Reg, uint8_t *pBuffer, uint16_t Length)
{
  if (!I2C3_BusLock()) return 1;
  HAL_StatusTypeDef status = HAL_OK;

  status = HAL_I2C_Mem_Read(&hi2c3, Addr, (uint16_t)Reg, I2C_MEMADD_SIZE_8BIT, pBuffer, Length, I2c3Timeout);
  I2C3_BusUnlock();

  /* Проверка статуса обмена */
  if(status == HAL_OK)
  {
    return 0;
  }
  else
  {
    /* Переинициализация шины */
    //I2Cx_Error();

    return 1;
  }
}

/**
  * @brief  Чтение 4 байт с устройства.
  * @param  ReadSize: количество байт для чтения (макс. 4)
  * @retval значение, прочитанное по SPI
  */
static uint32_t SPI5_Read(uint8_t ReadSize)
{
  HAL_StatusTypeDef status = HAL_OK;
  uint32_t readvalue;

  status = HAL_SPI_Receive(&hspi5, (uint8_t*) &readvalue, ReadSize, Spi5Timeout);

  /* Проверка статуса обмена */
  if(status != HAL_OK)
  {
    /* Переинициализация шины */
    SPI5_Error();
  }

  return readvalue;
}

/**
  * @brief  Запись байта в устройство.
  * @param  Value: значение для записи
  */
static void SPI5_Write(uint16_t Value)
{
  HAL_StatusTypeDef status = HAL_OK;

  status = HAL_SPI_Transmit(&hspi5, (uint8_t*) &Value, 1, Spi5Timeout);

  /* Проверка статуса обмена */
  if(status != HAL_OK)
  {
    /* Переинициализация шины */
    SPI5_Error();
  }
}

/**
  * @brief  Обработка ошибки SPI5.
  */
static void SPI5_Error(void)
{
  /* Деинициализация шины SPI */
  //HAL_SPI_DeInit(&SpiHandle);

  /* Переинициализация шины SPI */
  //SPIx_Init();
}

void LCD_IO_Init(void)
{
  /* Установить/сбросить управляющую линию */
  HAL_GPIO_WritePin(GPIOC, GPIO_PIN_2, GPIO_PIN_RESET);
  HAL_GPIO_WritePin(GPIOC, GPIO_PIN_2, GPIO_PIN_SET);
}

/**
  * @brief  Запись значения регистра.
  */
void LCD_IO_WriteData(uint16_t RegValue)
{
  /* Установить WRX для передачи данных */
  HAL_GPIO_WritePin(GPIOD, GPIO_PIN_13, GPIO_PIN_SET);

  /* Сбросить линию управления LCD (/CS) и передать данные */
  HAL_GPIO_WritePin(GPIOC, GPIO_PIN_2, GPIO_PIN_RESET);
  SPI5_Write(RegValue);

  /* Снять выбор: CS в 1 */
  HAL_GPIO_WritePin(GPIOC, GPIO_PIN_2, GPIO_PIN_SET);
}

/**
  * @brief  Запись адреса регистра.
  */
void LCD_IO_WriteReg(uint8_t Reg)
{
  /* Сбросить WRX для передачи команды */
  HAL_GPIO_WritePin(GPIOD, GPIO_PIN_13, GPIO_PIN_RESET);

  /* Сбросить линию управления LCD (/CS) и передать команду */
  HAL_GPIO_WritePin(GPIOC, GPIO_PIN_2, GPIO_PIN_RESET);
  SPI5_Write(Reg);

  /* Снять выбор: CS в 1 */
  HAL_GPIO_WritePin(GPIOC, GPIO_PIN_2, GPIO_PIN_SET);
}

/**
  * @brief  Reads register value.
  * @param  RegValue Address of the register to read
  * @param  ReadSize Number of bytes to read
  * @retval Content of the register value
  */
uint32_t LCD_IO_ReadData(uint16_t RegValue, uint8_t ReadSize)
{
  uint32_t readvalue = 0;

  /* Select: Chip Select low */
  HAL_GPIO_WritePin(GPIOC, GPIO_PIN_2, GPIO_PIN_RESET);

  /* Reset WRX to send command */
  HAL_GPIO_WritePin(GPIOD, GPIO_PIN_13, GPIO_PIN_RESET);

  SPI5_Write(RegValue);

  readvalue = SPI5_Read(ReadSize);

  /* Set WRX to send data */
  HAL_GPIO_WritePin(GPIOD, GPIO_PIN_13, GPIO_PIN_SET);

  /* Deselect: Chip Select high */
  HAL_GPIO_WritePin(GPIOC, GPIO_PIN_2, GPIO_PIN_SET);

  return readvalue;
}

/**
  * @brief  Wait for loop in ms.
  * @param  Delay in ms.
  */
void LCD_Delay(uint32_t Delay)
{
  HAL_Delay(Delay);
}

/* USER CODE END 4 */

void StartDefaultTask(void *argument)
{
  for(;;)
  {
    osDelay(1);
  }
}

void HandleDataProcessing(void *argument)
{
  /* USER CODE BEGIN HandleDataProcessing */
  /* Infinite loop */
  for(;;)
  {
    DataFunc_C();
  }
  /* USER CODE END HandleDataProcessing */
}

void ReadDataFunction(void *argument)
{
  /* USER CODE BEGIN ReadDataFunction */
  /* Infinite loop */
  for(;;)
  {
	ReadDataFunc_C();
  }
  /* USER CODE END ReadDataFunction */
}

  /* USER CODE BEGIN TransferToServer */
  /* Infinite loop */
void TransferToServer(void *argument)
{
  for(;;)
  {
	  TransferToServer_С();
  }
}
  /* USER CODE END TransferToServer */

/* Callback01 function */
void Callback01(void *argument)
{
  /* USER CODE BEGIN Callback01 */
	DataTimerFunc_C();
  /* USER CODE END Callback01 */
}

void HAL_TIM_PeriodElapsedCallback(TIM_HandleTypeDef *htim)
{
  if (htim->Instance == TIM6) {
    HAL_IncTick();
  }
}

void Error_Handler(void)
{
}

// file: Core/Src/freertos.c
/* USER CODE BEGIN Header */
/**
  ******************************************************************************
  * File Name          : freertos.c
  * Description        : Code for freertos applications
  ******************************************************************************
  * @attention
  *
  * <h2><center>&copy; Copyright (c) 2020 STMicroelectronics.
  * All rights reserved.</center></h2>
  *
  * This software component is licensed by ST under Ultimate Liberty license
  * SLA0044, the "License"; You may not use this file except in compliance with
  * the License. You may obtain a copy of the License at:
  *                             www.st.com/SLA0044
  *
  ******************************************************************************
  */
/* USER CODE END Header */

#include "FreeRTOS.h"
#include "task.h"
#include "main.h"

/* Hook prototypes */
void configureTimerForRunTimeStats(void);
unsigned long getRunTimeCounterValue(void);
void vApplicationStackOverflowHook(TaskHandle_t xTask, char *pcTaskName);

/* USER CODE BEGIN 1 */
/* Functions needed when configGENERATE_RUN_TIME_STATS is on */
__weak void configureTimerForRunTimeStats(void)
{
	CoreDebug->DEMCR |= CoreDebug_DEMCR_TRCENA_Msk;
	DWT->CTRL |= 1;
	DWT->CYCCNT = 0;

}

__weak unsigned long getRunTimeCounterValue(void)
{
return DWT->CYCCNT;
}

/* Вызывается ядром при обнаружении переполнения стека задачи (configCHECK_FOR_STACK_OVERFLOW == 2). */
void vApplicationStackOverflowHook(TaskHandle_t xTask, char *pcTaskName)
{
	(void)xTask;
	(void)pcTaskName;
	/* Фиксируем причину и перезапускаем МК, чтобы не оставлять "белый экран". */
	g_bootFaultMarker = BOOT_FAULT_MARKER_STACKOVERFLOW;
	g_bootFaultCounter++;
	__DSB();
	__ISB();
	NVIC_SystemReset();
}
/* USER CODE END 1 */
